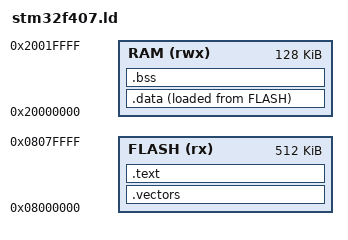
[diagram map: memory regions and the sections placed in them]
/* STM32F407 Memory Layout */
MEMORY
{
    FLASH (rx) : ORIGIN = 0x08000000, LENGTH = 512K
    /* Use the 128KB SRAM1/SRAM2 block at 0x20000000 (exclude CCM at 0x10000000) */
    RAM (rwx)   : ORIGIN = 0x20000000, LENGTH = 128K
}

SECTIONS
{
    .vectors :
    {
        KEEP(*(.vectors))
    } > FLASH

    .text :
    {
        *(.text*)
        *(.rodata*)
    } > FLASH

    .data :
    {
        _sdata = .;
        *(.data*)
        _edata = .;
    } > RAM AT > FLASH
    _ldata = LOADADDR(.data);

    .bss :
    {
        _sbss = .;
        *(.bss*)
        *(COMMON)
        _ebss = .;
    } > RAM

    _estack = ORIGIN(RAM) + LENGTH(RAM);
}
